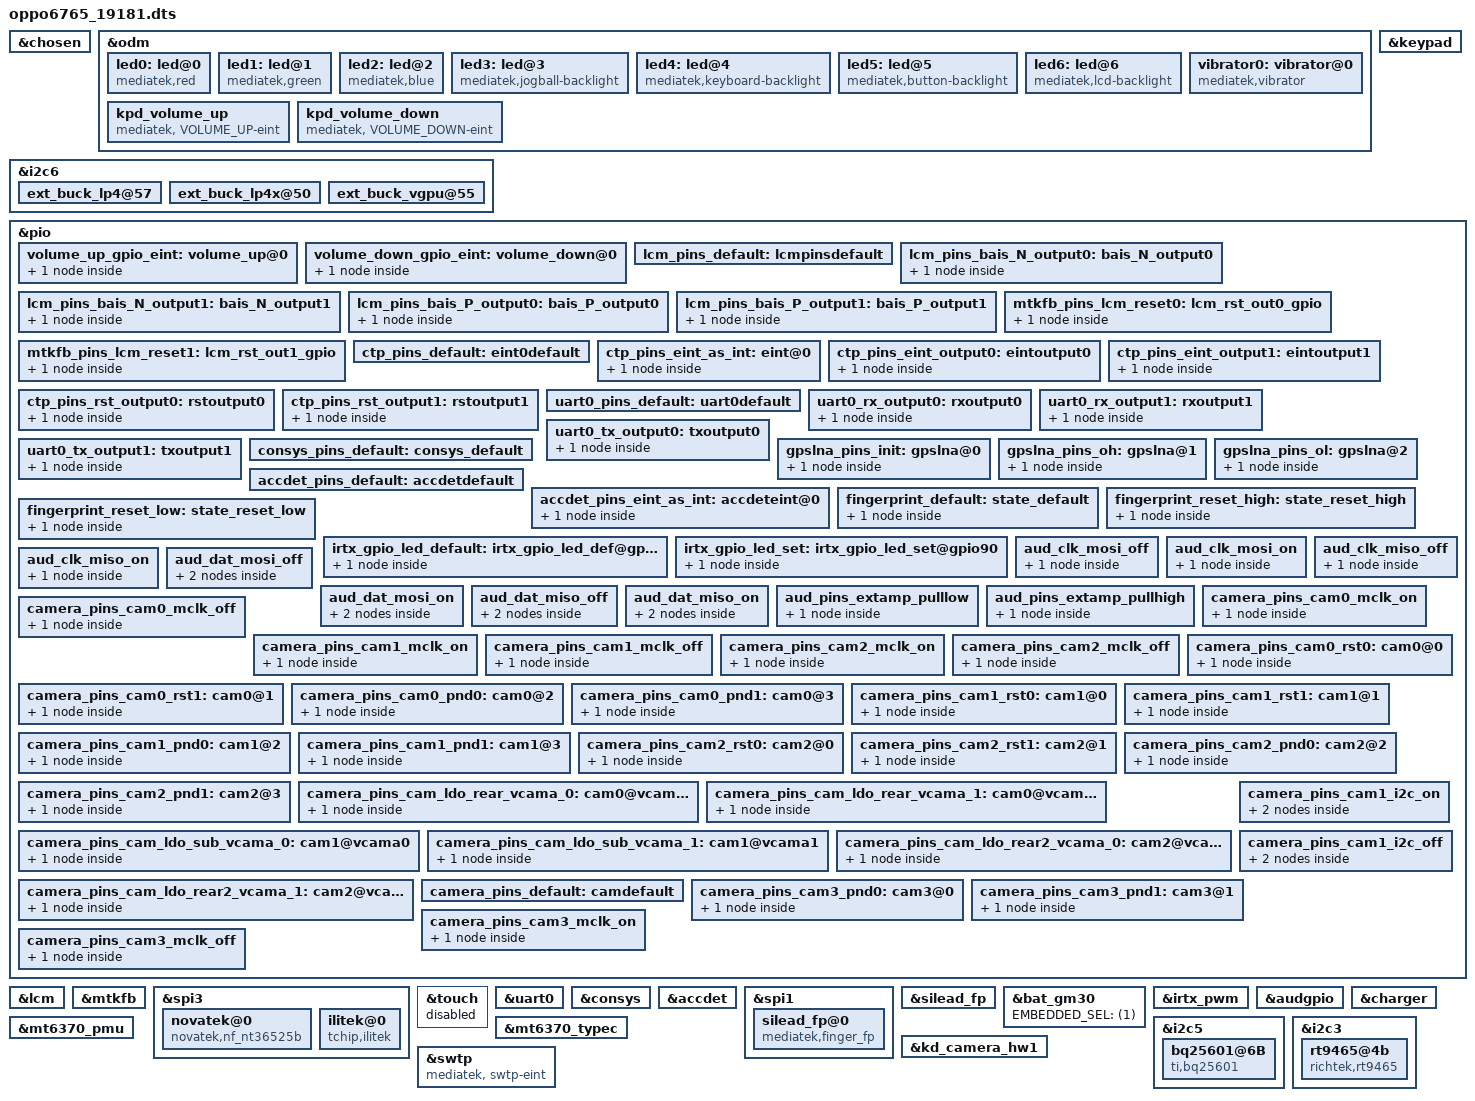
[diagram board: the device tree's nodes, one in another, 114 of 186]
#include <dt-bindings/interrupt-controller/arm-gic.h>
#include <dt-bindings/interrupt-controller/irq.h>
#include <dt-bindings/pinctrl/mt6765-pinfunc.h>
#include <dt-bindings/clock/mt6765-clk.h>

/dts-v1/;
/plugin/;

/* chosen */
&chosen {

	/* fpga may has no lk, we need to specify display info here */
	/* fb buffer is reserved using this dts by memory node above */
	atag,videolfb-fb_base_h = <0x0>;
	atag,videolfb-fb_base_l = <0x5e605000>;
	atag,videolfb-islcmfound = <1>;
	/* because no lk, so lcm is not inited */
	atag,videolfb-islcm_inited = <0>;
	atag,videolfb-fps= <6000>;
	atag,videolfb-vramSize= <0x017bb000>;
	atag,videolfb-lcmname= "nt35695B_fhd_dsi_cmd_auo_rt5081_drv";
};

&odm {
	led0:led@0 {
		compatible = "mediatek,red";
		led_mode = <0>;
		data = <1>;
		pwm_config = <0 0 0 0 0>;
	};
	led1:led@1 {
		compatible = "mediatek,green";
		led_mode = <0>;
		data = <1>;
		pwm_config = <0 0 0 0 0>;
	};
	led2:led@2 {
		compatible = "mediatek,blue";
		led_mode = <0>;
		data = <1>;
		pwm_config = <0 0 0 0 0>;
	};
	led3:led@3 {
		compatible = "mediatek,jogball-backlight";
		led_mode = <0>;
		data = <1>;
		pwm_config = <0 0 0 0 0>;
	};
	led4:led@4 {
		compatible = "mediatek,keyboard-backlight";
		led_mode = <0>;
		data = <1>;
		pwm_config = <0 0 0 0 0>;
	};
	led5:led@5 {
		compatible = "mediatek,button-backlight";
		led_mode = <0>;
		data = <1>;
		pwm_config = <0 0 0 0 0>;
	};
	led6:led@6 {
		compatible = "mediatek,lcd-backlight";
/* Sunshiyue@ODM.Muiltimedia.lcm  2019/9/21 modify for bring up lcm */
		led_mode = <4>;
		data = <1>;
		pwm_config = <0 3 0 0 0>;
	};
	vibrator0:vibrator@0 {
		compatible = "mediatek,vibrator";
		vib_timer = <25>;
		vib_limit = <9>;
/* zhangmengchun@ODM.BSP.vibrator  2018/11/28 modify for bring up vibrator */
		vib_vol= <11>;
	};

/*Liujia@ODM.System.keypad  2019/9/30 add vol+ vol- */
	kpd_volume_up:kpd_volume_up {
		compatible = "mediatek, VOLUME_UP-eint";
		interrupt-parent = <&pio>;
		interrupts = <93 IRQ_TYPE_EDGE_FALLING 93 0>;
		debounce = <32000>;
		status = "okay";
	};

	kpd_volume_down:kpd_volume_down {
		compatible = "mediatek, VOLUME_DOWN-eint";
		interrupt-parent = <&pio>;
		interrupts = <94 IRQ_TYPE_EDGE_FALLING 94 0>;
		debounce = <32000>;
		status = "okay";
	};
};

&i2c6 {
	ext_buck_lp4@57 {
		regulator-name ="ext_buck_vdd2";
		regulator-min-microvolt = <300000>;
		regulator-max-microvolt = <1300000>;
		vsel_pin = <0>;
	};

	ext_buck_lp4x@50 {
		regulator-name ="ext_buck_vddq";
		regulator-min-microvolt = <300000>;
		regulator-max-microvolt = <1300000>;
		vsel_pin = <1>;
	};
};

&i2c6 {
	ext_buck_vgpu@55 {
		regulator-name ="ext_buck_vgpu";
		regulator-min-microvolt = <300000>;
		regulator-max-microvolt = <1300000>;
		vsel_pin = <2>;
	};
};

/*Liujia@ODM.System.keypad  2019/9/30 add vol+ vol- */
&keypad {
	keypad,volume-up	= <&pio 93 0x00>;
	keypad,volume-down	= <&pio 94 0x00>;
	pinctrl-names = "volume_up_as_int", "volume_down_as_int";
	pinctrl-0 = <&volume_up_gpio_eint>;
	pinctrl-1 = <&volume_down_gpio_eint>;
	status = "okay";
};

&pio {
	volume_up_gpio_eint:volume_up@0{
		pins_cmd_dat {
			pinmux = <PINMUX_GPIO93__FUNC_GPIO93>;
			slew-rate = <0>;  /*direction 0:in, 1:out*/
			input-enable;
		};
	};

	volume_down_gpio_eint:volume_down@0{
		pins_cmd_dat {
			pinmux = <PINMUX_GPIO94__FUNC_GPIO94>;
			slew-rate = <0>;  /*direction 0:in, 1:out*/
			input-enable;
		};
	};
};

/* Sunshiyue@ODM.Muiltimedia.lcm  2019/9/21 modify for bring up lcm */
/* lcm moudle */
&lcm {
	pinctrl-names = "default", "state_bais_N_output0", "state_bais_N_output1",
		"state_bais_P_output0", "state_bais_P_output1";
	pinctrl-0 = <&lcm_pins_default>;
	pinctrl-1 = <&lcm_pins_bais_N_output0>;
	pinctrl-2 = <&lcm_pins_bais_N_output1>;
	pinctrl-3 = <&lcm_pins_bais_P_output0>;
	pinctrl-4 = <&lcm_pins_bais_P_output1>;
	status = "okay";
};
&pio {
	lcm_pins_default: lcmpinsdefault {
	};
	lcm_pins_bais_N_output0: bais_N_output0 {
		pins_cmd_dat {
			pinmux = <PINMUX_GPIO165__FUNC_GPIO165>;
			slew-rate = <1>;
			output-low;
		};
	};
	lcm_pins_bais_N_output1: bais_N_output1 {
		pins_cmd_dat {
			pinmux = <PINMUX_GPIO165__FUNC_GPIO165>;
			slew-rate = <1>;
			output-high;
		};
	};
	lcm_pins_bais_P_output0: bais_P_output0 {
		pins_cmd_dat {
			pinmux = <PINMUX_GPIO166__FUNC_GPIO166>;
			slew-rate = <1>;
			output-low;
		};
	};
	lcm_pins_bais_P_output1: bais_P_output1 {
		pins_cmd_dat {
			pinmux = <PINMUX_GPIO166__FUNC_GPIO166>;
			slew-rate = <1>;
			output-high;
		};
	};
};
/* lcm moudle end */
/* Sunshiyue@ODM.Muiltimedia.lcm  2019/9/21 modify for lcm_rst by pinctrl */
/* DISPSYS GPIO standardization start*/
&pio {
        mtkfb_pins_lcm_reset0: lcm_rst_out0_gpio {
                pins_cmd_dat {
                        pinmux = <PINMUX_GPIO45__FUNC_GPIO45>;
                        slew-rate = <1>;
                        output-low;
                };
        };
        mtkfb_pins_lcm_reset1: lcm_rst_out1_gpio {
                pins_cmd_dat {
                        pinmux = <PINMUX_GPIO45__FUNC_GPIO45>;
                        slew-rate = <1>;
                        output-high;
                };
	};
};
&mtkfb {
        pinctrl-names ="lcm_rst_out0_gpio",  "lcm_rst_out1_gpio";
        pinctrl-0 = <&mtkfb_pins_lcm_reset0>;
        pinctrl-1 = <&mtkfb_pins_lcm_reset1>;
        status = "okay";
};
/* DISPSYS GPIO standardization end*/

/* TOUCH start */

&spi3 {
	novatek@0 {
		compatible = "novatek,nf_nt36525b";
		reg = <0>;
		chip-name = "NF_NT36525B";
		status = "okay";

		spi-max-frequency = <9600000>;	//4800000,9600000,15000000,19200000
		reset-gpio = <&pio 178 0x00>;
		lcd-reset-gpio = <&pio 45 0x00>;
		interrupt-parent = <&pio>;
		interrupts = <0 IRQ_TYPE_EDGE_FALLING 0 0>;
		irq-gpio = <&pio 0 0x2002>;

		touchpanel,max-num-support = <10>;
		touchpanel,tx-rx-num = <18 32>;
		touchpanel,panel-coords = <720 1600>;
		touchpanel,display-coords = <720 1600>;
		touchpanel,touchmajor-limit = <0 54>;

		pinctrl-names = "default", "state_eint_as_int", "state_eint_output0",
							"state_eint_output1", "state_rst_output0", "state_rst_output1";
			pinctrl-0 = <&ctp_pins_default>;
			pinctrl-1 = <&ctp_pins_eint_as_int>;
			pinctrl-2 = <&ctp_pins_eint_output0>;
			pinctrl-3 = <&ctp_pins_eint_output1>;
			pinctrl-4 = <&ctp_pins_rst_output0>;
			pinctrl-5 = <&ctp_pins_rst_output1>;

		incell_screen;
		fw_edge_limit_support;
		black_gesture_support;
		charger_pump_support;
		headset_pump_support;
		esd_handle_support;
		//spurious_fingerprint_support;
		//lcd_trigger_fp_check;
		black_gesture_test_support;
		noflash_support;
		smart_gesture_support;
		pressure_report_support;
		fw_update_app_support;
		game_switch_support;
		drlimit_remove_support;
		lcd_trigger_load_tp_fw_support;
		//fw_update_in_probe_with_headfile;

		touchpanel,button-type = <4>;
	};
	ilitek@0 {
			compatible = "tchip,ilitek";
			reg = <0>;
			chip-name = "NF_ILI9881H";
			status = "okay";

			spi-max-frequency = <12000000>; //4800000,9600000,15000000,19200000
			reset-gpio = <&pio 178 0x00>;
			interrupt-parent = <&pio>;
			interrupts = <0 IRQ_TYPE_EDGE_FALLING 0 0>;
			irq-gpio = <&pio 0 0x2002>;

			touchpanel,max-num-support = <10>;
			touchpanel,tx-rx-num = <18 32>;
			touchpanel,panel-coords = <720 1600>;
			touchpanel,display-coords = <720 1600>;
			touchpanel,touchmajor-limit = <0 54>;

			pinctrl-names = "default", "state_eint_as_int", "state_eint_output0",
							"state_eint_output1", "state_rst_output0", "state_rst_output1";
			pinctrl-0 = <&ctp_pins_default>;
			pinctrl-1 = <&ctp_pins_eint_as_int>;
			pinctrl-2 = <&ctp_pins_eint_output0>;
			pinctrl-3 = <&ctp_pins_eint_output1>;
			pinctrl-4 = <&ctp_pins_rst_output0>;
			pinctrl-5 = <&ctp_pins_rst_output1>;

			//pinctrl-names = "default", "suspend";
			//pinctrl-0 = <&ts_int_active &ts_reset_active>;
			//pinctrl-1 = <&ts_int_suspend &ts_reset_suspend>;

			incell_screen;
			fw_edge_limit_support;
			black_gesture_support;
			charger_pump_support;
			headset_pump_support;
			esd_handle_support;
			//spurious_fingerprint_support;
			//lcd_trigger_fp_check;
			black_gesture_test_support;
			noflash_support;
			smart_gesture_support;
			pressure_report_support;
			fw_update_app_support;
			game_switch_support;
			drlimit_remove_support;
			lcd_trigger_load_tp_fw_support;
			suspend_gesture_cfg;
			//fw_update_in_probe_with_headfile;

			touchpanel,button-type = <4>;
	};
};
&touch {
/* zhangmengchun@ODM.Muiltimedia.tp  2018/11/28 modify for bring up TP */
	tpd-resolution = <720 1560>;
	use-tpd-button = <0>;
	tpd-key-num = <3>;
	tpd-key-local= <139 172 158 0>;
	tpd-key-dim-local = <90 883 100 40 230
				 883 100 40 370 883 100 40 0 0 0 0>;
/* zhangmengchun@ODM.Muiltimedia.tp  2018/11/28 modify for bring up TP */
	tpd-max-touch-num = <10>;
	tpd-filter-enable = <0>;
	tpd-filter-pixel-density = <146>;
	tpd-filter-custom-prameters = <0 0 0 0 0 0 0 0 0 0 0 0>;
	tpd-filter-custom-speed = <0 0 0>;
	status = "disabled";
};
&pio {
	ctp_pins_default: eint0default {
	};
	ctp_pins_eint_as_int: eint@0 {
		pins_cmd_dat {
			pinmux = <PINMUX_GPIO0__FUNC_GPIO0>;
			slew-rate = <0>;
			bias-disable;
		};
	};
	ctp_pins_eint_output0: eintoutput0 {
		pins_cmd_dat {
			pinmux = <PINMUX_GPIO0__FUNC_GPIO0>;
			slew-rate = <1>;
			output-low;
		};
	};
	ctp_pins_eint_output1: eintoutput1 {
		pins_cmd_dat {
			pinmux = <PINMUX_GPIO0__FUNC_GPIO0>;
			slew-rate = <1>;
			output-high;
		};
	};
	ctp_pins_rst_output0: rstoutput0 {
		pins_cmd_dat {
/* zhangmengchun@ODM.Muiltimedia.tp  2018/11/28 modify for bring up TP */
			pinmux = <PINMUX_GPIO178__FUNC_GPIO178>;
			slew-rate = <1>;
			output-low;
		};
	};
	ctp_pins_rst_output1: rstoutput1 {
		pins_cmd_dat {
/* zhangmengchun@ODM.Muiltimedia.tp  2018/11/28 modify for bring up TP */
			pinmux = <PINMUX_GPIO178__FUNC_GPIO178>;
			slew-rate = <1>;
			output-high;
		};
	};
};
/* TOUCH end */
/*serial start*/
/*Wenchao.Du@BSP.Kernel.Driver 2019/01/17 disable uart for user*/
&uart0 {
	pinctrl-names = "default", "state_uart0_rx_output0", "state_uart0_rx_output1",
		"state_uart0_tx_output0", "state_uart0_tx_output1";
	pinctrl-0 = <&uart0_pins_default>;
	pinctrl-1 = <&uart0_rx_output0>;
	pinctrl-2 = <&uart0_rx_output1>;
	pinctrl-3 = <&uart0_tx_output0>;
	pinctrl-4 = <&uart0_tx_output1>;
	status = "okay";
};
&pio {
	uart0_pins_default: uart0default {
	};
	uart0_rx_output0: rxoutput0 {
		pins_cmd_dat {
			pinmux = <PINMUX_GPIO95__FUNC_GPIO95>;
			slew-rate = <1>;
			output-low;
		};
	};
	uart0_rx_output1: rxoutput1 {
		pins_cmd_dat {
			pinmux = <PINMUX_GPIO95__FUNC_GPIO95>;
			slew-rate = <1>;
			output-high;
		};
	};
	uart0_tx_output0: txoutput0 {
		pins_cmd_dat {
			pinmux = <PINMUX_GPIO96__FUNC_GPIO96>;
			slew-rate = <1>;
			output-low;
		};
	};
	uart0_tx_output1: txoutput1 {
		pins_cmd_dat {
			pinmux = <PINMUX_GPIO96__FUNC_GPIO96>;
			slew-rate = <1>;
			output-high;
		};
	};
};
/*serial end*/
/* CONSYS GPIO standardization */
&pio {
	consys_pins_default: consys_default {
	};
	gpslna_pins_init: gpslna@0 {
		pins_cmd_dat {
			pinmux = <PINMUX_GPIO91__FUNC_GPIO91>;
			slew-rate = <0>;
			bias-disable;
			output-low;
		};
	};
	gpslna_pins_oh: gpslna@1 {
		pins_cmd_dat {
			pinmux = <PINMUX_GPIO91__FUNC_GPIO91>;
			slew-rate = <1>;
			output-high;
		};
	};
	gpslna_pins_ol: gpslna@2 {
		pins_cmd_dat {
			pinmux = <PINMUX_GPIO91__FUNC_GPIO91>;
			slew-rate = <1>;
			output-low;
		};
	};
};
&consys {
	pinctrl-names = "default", "gps_lna_state_init",
		"gps_lna_state_oh", "gps_lna_state_ol";
	pinctrl-0 = <&consys_pins_default>;
	pinctrl-1 = <&gpslna_pins_init>;
	pinctrl-2 = <&gpslna_pins_oh>;
	pinctrl-3 = <&gpslna_pins_ol>;
	status = "okay";
};
/* CONSYS end */

/* accdet start */
&accdet {
	accdet-mic-vol = <6>;
	headset-mode-setting = <0x500 0x500 1 0x1f0 0x800 0x800 0x20 0x44>;
	accdet-plugout-debounce = <1>;
	accdet-mic-mode = <1>;
	headset-eint-level-pol = <8>;
	headset-three-key-threshold = <0 80 220 400>;
	headset-three-key-threshold-CDD = <0 121 192 600>;
	headset-four-key-threshold = <0 58 121 192 400>;
	pinctrl-names = "default", "state_eint_as_int";
	pinctrl-0 = <&accdet_pins_default>;
	pinctrl-1 = <&accdet_pins_eint_as_int>;
	status = "okay";
};
&pio {
	accdet_pins_default: accdetdefault {
	};
	accdet_pins_eint_as_int: accdeteint@0 {
		pins_cmd_dat {
			pinmux = <PINMUX_GPIO9__FUNC_GPIO9>;
			slew-rate = <0>;
			bias-disable;
		};
	};
};
/* accdet end */

/*FINGERPRINT start */
&spi1 {
	#address-cells = <1>;
	#size-cells = <0>;
	silead_fp@0 {
		compatible = "mediatek,finger_fp";
		reg = <0>;
		spi-id = <1>;
		spi-irq = <122>;
		spi-reg = <0x11010000>;
		spi-max-frequency = <8000000>;
		netlink-event = <30>;
		status = "okay";
	};
};

&silead_fp {
	pinctrl-names = "default", "reset_high", "reset_low";
	pinctrl-0 = <&fingerprint_default>;
	pinctrl-1 = <&fingerprint_reset_high>;
	pinctrl-2 = <&fingerprint_reset_low>;
	status = "okay";
};

&pio {
	fingerprint_default: state_default {
	pins_cmd_dat {
			pinmux = <PINMUX_GPIO3__FUNC_GPIO3>;
			slew-rate = <0>;
			bias-disable;
		};
	};
	fingerprint_reset_high: state_reset_high {
		pins_cmd_dat {
			pinmux = <PINMUX_GPIO171__FUNC_GPIO171>;
			slew-rate = <1>;
			output-high;
		};
	};
	fingerprint_reset_low: state_reset_low {
		pins_cmd_dat {
			pinmux = <PINMUX_GPIO171__FUNC_GPIO171>;
			slew-rate = <1>;
			output-low;
		};
	};
};

/*FINGERPRINT end */

/* battery end */
&bat_gm30 {
	EMBEDDED_SEL = <(1)>;
};
/* battery end */

/* IRTX GPIO end */
&irtx_pwm {
	pinctrl-names = "irtx_gpio_led_default", "irtx_gpio_led_set";
	pinctrl-0 = <&irtx_gpio_led_default>;
	pinctrl-1 = <&irtx_gpio_led_set>;
	status = "okay";
};
&pio {
	irtx_gpio_led_default:irtx_gpio_led_def@gpio90 {
		pins_cmd_dat {
			pinmux = <PINMUX_GPIO90__FUNC_GPIO90>;
			slew-rate = <1>;
			bias-disable;
			output-low;
			input-schmitt-enable = <0>;
		};
	};

	irtx_gpio_led_set:irtx_gpio_led_set@gpio90 {
		pins_cmd_dat {
			pinmux = <PINMUX_GPIO90__FUNC_PWM0>;
			slew-rate = <1>;
			output-high;
		};
	};
};
/* IRTX GPIO Settings -End */

/* AUDIO GPIO standardization */
&audgpio {
	pinctrl-names = "aud_clk_mosi_off",
			"aud_clk_mosi_on",
			"aud_clk_miso_off",
			"aud_clk_miso_on",
			"aud_dat_mosi_off",
			"aud_dat_mosi_on",
			"aud_dat_miso_off",
			"aud_dat_miso_on",
/* zhangmengchun@ODM.Muiltimedia.audio  2018/11/28 modify for bring up audio */
			"extamp-pulllow",
			"extamp-pullhigh";
	pinctrl-0 = <&aud_clk_mosi_off>;
	pinctrl-1 = <&aud_clk_mosi_on>;
	pinctrl-2 = <&aud_clk_miso_off>;
	pinctrl-3 = <&aud_clk_miso_on>;
	pinctrl-4 = <&aud_dat_mosi_off>;
	pinctrl-5 = <&aud_dat_mosi_on>;
	pinctrl-6 = <&aud_dat_miso_off>;
	pinctrl-7 = <&aud_dat_miso_on>;
/* zhangmengchun@ODM.Muiltimedia.audio  2018/11/28 modify for bring up audio */
	pinctrl-8 = <&aud_pins_extamp_pulllow>;
	pinctrl-9 = <&aud_pins_extamp_pullhigh>;
	status = "okay";
	gpio_audio_pa_ctrl = <&pio 150 0>;
};

&pio {
	aud_clk_mosi_off: aud_clk_mosi_off {
		pins_cmd0_dat {
			pinmux = <PINMUX_GPIO136__FUNC_GPIO136>;
		};
	};

	aud_clk_mosi_on: aud_clk_mosi_on {
		pins_cmd0_dat {
			pinmux = <PINMUX_GPIO136__FUNC_AUD_CLK_MOSI>;
		};
	};

	aud_clk_miso_off: aud_clk_miso_off {
		pins_cmd0_dat {
			pinmux = <PINMUX_GPIO140__FUNC_GPIO140>;
		};
	};

	aud_clk_miso_on: aud_clk_miso_on {
		pins_cmd0_dat {
			pinmux = <PINMUX_GPIO140__FUNC_AUD_CLK_MISO>;
		};
	};

	aud_dat_mosi_off: aud_dat_mosi_off {
		pins_cmd1_dat {
			pinmux = <PINMUX_GPIO138__FUNC_GPIO138>;
			input-enable;
			slew-rate = <0>;
			bias-disable;
		};
		pins_cmd2_dat {
			pinmux = <PINMUX_GPIO139__FUNC_GPIO139>;
			input-enable;
			slew-rate = <0>;
			bias-disable;
		};
	};

	aud_dat_mosi_on: aud_dat_mosi_on {
		pins_cmd1_dat {
			pinmux = <PINMUX_GPIO138__FUNC_AUD_DAT_MOSI0>;
		};
		pins_cmd2_dat {
			pinmux = <PINMUX_GPIO139__FUNC_AUD_DAT_MOSI1>;
		};
	};

	aud_dat_miso_off: aud_dat_miso_off {
		pins_cmd1_dat {
			pinmux = <PINMUX_GPIO142__FUNC_GPIO142>;
			input-enable;
			slew-rate = <0>;
			bias-disable;
		};
		pins_cmd2_dat {
			pinmux = <PINMUX_GPIO143__FUNC_GPIO143>;
			input-enable;
			slew-rate = <0>;
			bias-disable;
		};
	};

	aud_dat_miso_on: aud_dat_miso_on {
		pins_cmd1_dat {
			pinmux = <PINMUX_GPIO142__FUNC_AUD_DAT_MISO0>;
		};
		pins_cmd2_dat {
			pinmux = <PINMUX_GPIO143__FUNC_AUD_DAT_MISO1>;
		};
	};

/* zhangmengchun@ODM.Muiltimedia.audio  2018/11/28 modify for bring up audio */
	aud_pins_extamp_pulllow: aud_pins_extamp_pulllow {
		pins_cmd_dat {
			pinmux = <PINMUX_GPIO150__FUNC_GPIO150>;
			slew-rate = <1>;
			output-low;
		};
	};

	aud_pins_extamp_pullhigh: aud_pins_extamp_pullhigh {
		pins_cmd_dat {
			pinmux = <PINMUX_GPIO150__FUNC_GPIO150>;
			slew-rate = <1>;
			output-high;
		};
	};
};
/* AUDIO end */

&mt6370_pmu {
	mt6370,intr_gpio_num = <11>; /* direct defined GPIO num */
	mt6370,intr_gpio = <&pio 11 0x0>;
};

&mt6370_typec {
	mt6370pd,intr_gpio_num = <41>; /* direct defined GPIO num */
	mt6370pd,intr_gpio = <&pio 41 0x0>;
};

&charger {
/*Hanxing.Duan@ODM.BSP.CHG.Basic 2018/11/28 modify for bring up charger start */
	algorithm_name = "SwitchCharging";
	chg1_ta_ac_charger_current = <2000000>;
	chg2_ta_ac_charger_current = <2000000>;
	qcom,input_current_charger_ma = <2000>;
	qcom,input_current_usb_ma = <500>;
	qcom,input_current_cdp_ma = <1500>;
	qcom,input_current_led_ma = <1200>;
	qcom,input_current_led_ma_high = <1200>;     //led on limit 1.2A
	qcom,input_current_led_ma_warm = <1200>;     //led on limit 1.2A
	qcom,input_current_led_ma_normal = <1200>;   //led on limit 1.2A

	qcom,input_current_camera_ma = <1200>;
	qcom,input_current_calling_ma = <900>;
	qcom,charge_current_calling_ma = <500>;

	qcom,overtemp_bat_decidegc = <350>;
	qcom,iterm_disabled = <0>;
	qcom,iterm_ma = <205>;
	qcom,recharge-mv = <100>;

	qcom,batt_capacity_mah = <4230>; /*typical capacity*/
	//qcom,batt_capacity_mah = <3900>; /*rated capacity*/

	qcom,removed_bat_decidegc = <190>;  /* < -19C */

	qcom,cold_bat_decidegc = <20>;  /* -2C ~ 0C */
	qcom,temp_cold_vfloat_mv = <3980>;
	qcom,temp_cold_fastchg_current_ma = <360>;

	qcom,little_cold_bat_decidegc = <0>;	/* 0C ~ 5C */
	qcom,temp_little_cold_vfloat_mv = <4385>;
	qcom,temp_little_cold_fastchg_current_ma_high = <550>;
	qcom,temp_little_cold_fastchg_current_ma_low = <550>;
	qcom,temp_little_cold_fastchg_current_ma = <550>;

	qcom,cool_bat_decidegc = <50>;	/* 5C ~ 12C */
	qcom,temp_cool_vfloat_mv = <4385>;
	qcom,temp_cool_fastchg_current_ma_high = <1250>;
	qcom,temp_cool_fastchg_current_ma_low = <650>;

	qcom,little_cool_bat_decidegc = <120>;	/* 12C ~ 16C */
	qcom,temp_little_cool_vfloat_mv = <4385>;
	qcom,temp_little_cool_fastchg_current_ma = <1700>;

	qcom,normal_bat_decidegc = <160>;	/* 16C ~ 45C */
	qcom,temp_normal_fastchg_current_ma = <2000>;
	qcom,temp_normal_vfloat_mv = <4385>;

	qcom,warm_bat_decidegc = <450>;		/* 45C ~ 53C */ /*8pin Bat Vooc project need add 3 degree C*/
	qcom,temp_warm_vfloat_mv = <4130>;
	qcom,temp_warm_fastchg_current_ma = <1250>;
	qcom,temp_warm_fastchg_current_ma_led_on = <500>;

	qcom,hot_bat_decidegc = <530>;  /* > 53C */

	qcom,non_standard_vfloat_mv = <3980>;
	qcom,non_standard_fastchg_current_ma = <512>;


	qcom,cold_vfloat_sw_limit = <3930>;
	qcom,little_cold_vfloat_sw_limit = <4335>;
	qcom,cool_vfloat_sw_limit = <4335>;
	qcom,little_cool_vfloat_sw_limit = <4335>;
	qcom,normal_vfloat_sw_limit = <4335>;
	qcom,warm_vfloat_sw_limit = <4080>;
	qcom,non_standard_vfloat_sw_limit = <3930>;

	qcom,max_chg_time_sec = <36000>;
	qcom,charger_hv_thr = <5800>;
	qcom,charger_lv_thr = <3400>;
	qcom,vbatt_full_thr = <4400>;
	qcom,vbatt_hv_thr = <4500>;

	qcom,vfloat_step_mv = <16>;
	qcom,non_standard_vfloat_over_sw_limit = <3980>;
	qcom,cold_vfloat_over_sw_limit = <3980>;
	qcom,little_cold_vfloat_over_sw_limit = <4401>;
	qcom,cool_vfloat_over_sw_limit = <4401>;
	qcom,little_cool_vfloat_over_sw_limit = <4401>;
	qcom,normal_vfloat_over_sw_limit = <4401>;
	qcom,warm_vfloat_over_sw_limit = <4150>;

	qcom,vbatt_power_off = <3300>;
	qcom,vbatt_soc_1 = <3410>;
	qcom,vooc_project = <0>;
	qcom,vbatt_num = <1>;

	qcom,normal_vterm_hw_inc = <20>;
	qcom,non_normal_vterm_hw_inc = <20>;



	qcom,default_iterm_ma = <205>;
	qcom,default_temp_normal_fastchg_current_ma = <2100>;
	qcom,default_normal_vfloat_sw_limit = <4335>;
	qcom,default_temp_normal_vfloat_mv = <4385>;
	qcom,default_normal_vfloat_over_sw_limit = <4401>;

	qcom,check_batt_full_by_sw;
	qcom,chg_ctrl_by_lcd;
	qcom,chg_ctrl_by_camera;
	qcom,chg_ctrl_by_calling;
	qcom,sw_vfloat_over_protect_enable;
};

&i2c5 {
	bq25601@6B {
			compatible = "ti,bq25601";
			reg = <0x6b>;
			ti,bq2560x,usb-vlim = <4600>;
			ti,bq2560x,usb-ilim = <500>;
			ti,bq2560x,usb-vreg = <4400>;
			ti,bq2560x,usb-ichg = <500>;

			ti,bq2560x,precharge-current = <256>;
			ti,bq2560x,termination-current = <300>;
			ti,bq2560x,boost-voltage = <4998>;
			ti,bq2560x,boost-current = <1200>;
			ti,bq2560x,enable_term;
			ti,bq2560x,stat-pin-ctrl = <3>;
			ti,bq2560x,vac-ovp-threshold = <6500>;

	};

};
/*Hanxing.Duan@ODM.BSP.CHG.Basic 2018/11/28 add for bring up charger end */

&i2c3 {
	rt9465@4b {
		compatible = "richtek,rt9465";
		reg = <0x4b>;
		status = "okay";
		rt,en_gpio_num = <176>;
		rt,en_gpio = <&pio 176 0x0>;
		rt,intr_gpio_num = <23>; /* direct defined GPIO num */
		rt,intr_gpio = <&pio 23 0x0>;
		interrupt-names = "wdtmri";
		charger_name = "secondary_chg";
		ichg = <1500000>; /* uA */
		mivr = <4500000>; /* uV */
		cv = <4550000>; /* uV */
		ieoc = <700000>; /* uA */
		safety_timer = <12>; /* hour */
		en_st; /* safety timer */
		/* en_te; */
		en_wdt;
	};
};

&pio {
	camera_pins_cam0_mclk_on: camera_pins_cam0_mclk_on {
		pins_cmd_dat {
			pinmux = <PINMUX_GPIO99__FUNC_CMMCLK0>;
		};
	};
	camera_pins_cam0_mclk_off: camera_pins_cam0_mclk_off {
		pins_cmd_dat {
			pinmux = <PINMUX_GPIO99__FUNC_GPIO99>;
		};
	};
	camera_pins_cam1_mclk_on: camera_pins_cam1_mclk_on {
		pins_cmd_dat {
			pinmux = <PINMUX_GPIO100__FUNC_CMMCLK1>;
		};
	};
	camera_pins_cam1_mclk_off: camera_pins_cam1_mclk_off {
		pins_cmd_dat {
			pinmux = <PINMUX_GPIO100__FUNC_GPIO100>;
		};
	};
	camera_pins_cam2_mclk_on: camera_pins_cam2_mclk_on {
		pins_cmd_dat {
			pinmux = <PINMUX_GPIO108__FUNC_CMMCLK2>;
		};
	};
	camera_pins_cam2_mclk_off: camera_pins_cam2_mclk_off {
		pins_cmd_dat {
			pinmux = <PINMUX_GPIO108__FUNC_GPIO108>;
		};
	};
	camera_pins_cam0_rst0: cam0@0 {
		pins_cmd_dat {
			pinmux = <PINMUX_GPIO101__FUNC_GPIO101>;
			slew-rate = <1>;
			output-low;
		};
	};
	camera_pins_cam0_rst1: cam0@1 {
		pins_cmd_dat {
			pinmux = <PINMUX_GPIO101__FUNC_GPIO101>;
			slew-rate = <1>;
			output-high;
		};
	};
	camera_pins_cam0_pnd0: cam0@2 {
		pins_cmd_dat {
			pinmux = <PINMUX_GPIO97__FUNC_GPIO97>;
			slew-rate = <1>;
			output-low;
		};
	};
	camera_pins_cam0_pnd1: cam0@3 {
		pins_cmd_dat {
			pinmux = <PINMUX_GPIO97__FUNC_GPIO97>;
			slew-rate = <1>;
			output-high;
		};
	};
	camera_pins_cam1_rst0: cam1@0 {
		pins_cmd_dat {
			pinmux = <PINMUX_GPIO102__FUNC_GPIO102>;
			slew-rate = <1>;
			output-low;
		};
	};
	camera_pins_cam1_rst1: cam1@1 {
		pins_cmd_dat {
			pinmux = <PINMUX_GPIO102__FUNC_GPIO102>;
			slew-rate = <1>;
			output-high;
		};
	};
	camera_pins_cam1_pnd0: cam1@2 {
		pins_cmd_dat {
			pinmux = <PINMUX_GPIO98__FUNC_GPIO98>;
			slew-rate = <1>;
			output-low;
		};
	};
	camera_pins_cam1_pnd1: cam1@3 {
		pins_cmd_dat {
			pinmux = <PINMUX_GPIO98__FUNC_GPIO98>;
			slew-rate = <1>;
			output-high;
		};
	};
	camera_pins_cam2_rst0: cam2@0 {
		pins_cmd_dat {
			pinmux = <PINMUX_GPIO109__FUNC_GPIO109>;
			slew-rate = <1>;
			output-low;
		};
	};
	camera_pins_cam2_rst1: cam2@1 {
		pins_cmd_dat {
			pinmux = <PINMUX_GPIO109__FUNC_GPIO109>;
			slew-rate = <1>;
			output-high;
		};
	};
	camera_pins_cam2_pnd0: cam2@2 {
		pins_cmd_dat {
			pinmux = <PINMUX_GPIO107__FUNC_GPIO107>;
			slew-rate = <1>;
			output-low;
		};
	};
	camera_pins_cam2_pnd1: cam2@3 {
		pins_cmd_dat {
			pinmux = <PINMUX_GPIO107__FUNC_GPIO107>;
			slew-rate = <1>;
			output-high;
		};
	};
	camera_pins_cam_ldo_rear_vcama_0: cam0@vcama0 {
		pins_cmd_dat {
			pinmux = <PINMUX_GPIO156__FUNC_GPIO156>;
			slew-rate = <1>;
			output-low;
		};
	};
	camera_pins_cam_ldo_rear_vcama_1: cam0@vcama1 {
		pins_cmd_dat {
			pinmux = <PINMUX_GPIO156__FUNC_GPIO156>;
			slew-rate = <1>;
			output-high;
		};
	};
	camera_pins_cam_ldo_sub_vcama_0: cam1@vcama0 {
		pins_cmd_dat {
			pinmux = <PINMUX_GPIO155__FUNC_GPIO155>;
			slew-rate = <1>;
			output-low;
		};
	};
	camera_pins_cam_ldo_sub_vcama_1: cam1@vcama1 {
		pins_cmd_dat {
			pinmux = <PINMUX_GPIO155__FUNC_GPIO155>;
			slew-rate = <1>;
			output-high;
		};
	};
	camera_pins_cam_ldo_rear2_vcama_0: cam2@vcama0 {
		pins_cmd_dat {
			pinmux = <PINMUX_GPIO155__FUNC_GPIO155>;
			slew-rate = <1>;
			output-low;
		};
	};
	camera_pins_cam_ldo_rear2_vcama_1: cam2@vcama1 {
		pins_cmd_dat {
			pinmux = <PINMUX_GPIO155__FUNC_GPIO155>;
			slew-rate = <1>;
			output-high;
		};
	};
	camera_pins_default: camdefault {
	};
	camera_pins_cam1_i2c_on: camera_pins_cam1_i2c_on {
		pins_cmd1_dat {
			pinmux = <PINMUX_GPIO105__FUNC_SCL4>;
		};
		pins_cmd2_dat {
			pinmux = <PINMUX_GPIO106__FUNC_SDA4>;
		};
	};
    camera_pins_cam1_i2c_off: camera_pins_cam1_i2c_off {
		pins_cmd1_dat {
			pinmux = <PINMUX_GPIO105__FUNC_GPIO105>;
			slew-rate = <1>;
			output-low;
		};
		pins_cmd2_dat {
			pinmux = <PINMUX_GPIO106__FUNC_GPIO106>;
			slew-rate = <1>;
			output-low;
		};
	};
	camera_pins_cam3_pnd0: cam3@0 {
		pins_cmd_dat {
			pinmux = <PINMUX_GPIO160__FUNC_GPIO160>;
			slew-rate = <1>;
			output-low;
		};
	};
	camera_pins_cam3_pnd1: cam3@1 {
		pins_cmd_dat {
			pinmux = <PINMUX_GPIO160__FUNC_GPIO160>;
			slew-rate = <1>;
			output-high;
		};
	};
	camera_pins_cam3_mclk_on: camera_pins_cam3_mclk_on {
		pins_cmd_dat {
			pinmux = <PINMUX_GPIO88__FUNC_CMMCLK3>;
		};
	};
	camera_pins_cam3_mclk_off: camera_pins_cam3_mclk_off {
		pins_cmd_dat {
			pinmux = <PINMUX_GPIO88__FUNC_GPIO88>;
		};
	};
};

&kd_camera_hw1 {
	pinctrl-names = "default",
			"cam0_rst0",
			"cam0_rst1",
			"cam0_pnd0",
			"cam0_pnd1",
			"cam1_rst0",
			"cam1_rst1",
			"cam1_pnd0",
			"cam1_pnd1",
			"cam2_rst0",
			"cam2_rst1",
			"cam2_pnd0",
			"cam2_pnd1",
			"cam0_vcama_on",
			"cam0_vcama_off",
			"cam1_vcama_on",
			"cam1_vcama_off",
			"cam2_vcama_on",
			"cam2_vcama_off",
			"cam0_mclk_on",
			"cam0_mclk_off",
			"cam1_mclk_on",
			"cam1_mclk_off",
			"cam2_mclk_on",
			"cam2_mclk_off",
			"cam1_i2c_on",
			"cam1_i2c_off",
			"cam3_pnd1",
			"cam3_pnd0",
			"cam3_mclk_on",
			"cam3_mclk_off";

	pinctrl-0 = <&camera_pins_default>;
	pinctrl-1 = <&camera_pins_cam0_rst0>;
	pinctrl-2 = <&camera_pins_cam0_rst1>;
	pinctrl-3 = <&camera_pins_cam0_pnd0>;
	pinctrl-4 = <&camera_pins_cam0_pnd1>;
	pinctrl-5 = <&camera_pins_cam1_rst0>;
	pinctrl-6 = <&camera_pins_cam1_rst1>;
	pinctrl-7 = <&camera_pins_cam1_pnd0>;
	pinctrl-8 = <&camera_pins_cam1_pnd1>;
	pinctrl-9 = <&camera_pins_cam2_rst0>;
	pinctrl-10 = <&camera_pins_cam2_rst1>;
	pinctrl-11 = <&camera_pins_cam2_pnd0>;
	pinctrl-12 = <&camera_pins_cam2_pnd1>;
	pinctrl-13 = <&camera_pins_cam_ldo_rear_vcama_1>;
	pinctrl-14 = <&camera_pins_cam_ldo_rear_vcama_0>;
	pinctrl-15 = <&camera_pins_cam_ldo_sub_vcama_1>;
	pinctrl-16 = <&camera_pins_cam_ldo_sub_vcama_0>;
	pinctrl-17 = <&camera_pins_cam_ldo_rear2_vcama_1>;
	pinctrl-18 = <&camera_pins_cam_ldo_rear2_vcama_0>;
	pinctrl-19 = <&camera_pins_cam0_mclk_on>;
	pinctrl-20 = <&camera_pins_cam0_mclk_off>;
	pinctrl-21 = <&camera_pins_cam1_mclk_on>;
	pinctrl-22 = <&camera_pins_cam1_mclk_off>;
	pinctrl-23 = <&camera_pins_cam2_mclk_on>;
	pinctrl-24 = <&camera_pins_cam2_mclk_off>;
	pinctrl-25 = <&camera_pins_cam1_i2c_on>;
	pinctrl-26 = <&camera_pins_cam1_i2c_off>;
	pinctrl-27 = <&camera_pins_cam3_pnd1>;
	pinctrl-28 = <&camera_pins_cam3_pnd0>;
	pinctrl-29 = <&camera_pins_cam3_mclk_on>;
	pinctrl-30 = <&camera_pins_cam3_mclk_off>;
	status = "okay";

};

//#ifdef VENDOR_EDIT
//Anhui.Sun@PSW.NW.RF, 2018/12/19, Add for SWTP - RF cable detection
&swtp {
    compatible = "mediatek, swtp-eint";
};
//#endif  /*VENDOR_EDIT*/

#include <oppo6765_19181/cust.dtsi>
/*End of this file, DO NOT ADD ANYTHING HERE*/
